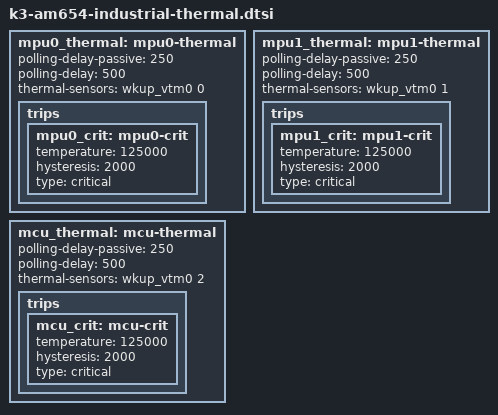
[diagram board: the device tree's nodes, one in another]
// SPDX-License-Identifier: GPL-2.0

#include <dt-bindings/thermal/thermal.h>

mpu0_thermal: mpu0-thermal {
	polling-delay-passive = <250>; /* milliseconds */
	polling-delay = <500>; /* milliseconds */
	thermal-sensors = <&wkup_vtm0 0>;

	trips {
		mpu0_crit: mpu0-crit {
			temperature = <125000>; /* milliCelsius */
			hysteresis = <2000>; /* milliCelsius */
			type = "critical";
		};
	};
};

mpu1_thermal: mpu1-thermal {
	polling-delay-passive = <250>; /* milliseconds */
	polling-delay = <500>; /* milliseconds */
	thermal-sensors = <&wkup_vtm0 1>;

	trips {
		mpu1_crit: mpu1-crit {
			temperature = <125000>; /* milliCelsius */
			hysteresis = <2000>; /* milliCelsius */
			type = "critical";
		};
	};
};

mcu_thermal: mcu-thermal {
	polling-delay-passive = <250>; /* milliseconds */
	polling-delay = <500>; /* milliseconds */
	thermal-sensors = <&wkup_vtm0 2>;

	trips {
		mcu_crit: mcu-crit {
			temperature = <125000>; /* milliCelsius */
			hysteresis = <2000>; /* milliCelsius */
			type = "critical";
		};
	};
};
